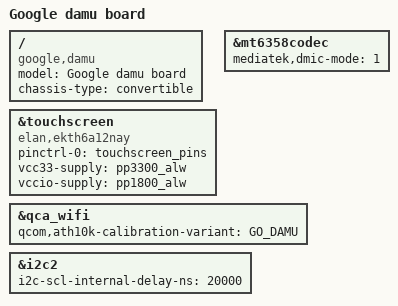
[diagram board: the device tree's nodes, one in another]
// SPDX-License-Identifier: (GPL-2.0 OR MIT)
/*
 * Copyright 2021 Google LLC
 */

/dts-v1/;
#include "mt8183-kukui-jacuzzi.dtsi"
#include "mt8183-kukui-audio-da7219-max98357a.dtsi"

/ {
	model = "Google damu board";
	chassis-type = "convertible";
	compatible = "google,damu", "mediatek,mt8183";
};

&touchscreen {
	compatible = "elan,ekth6a12nay";

	pinctrl-names = "default";
	pinctrl-0 = <&touchscreen_pins>;

	vcc33-supply = <&pp3300_alw>;
	vccio-supply = <&pp1800_alw>;
};

&mt6358codec {
	mediatek,dmic-mode = <1>; /* one-wire */
};

&qca_wifi {
	qcom,ath10k-calibration-variant = "GO_DAMU";
};

&i2c2 {
	i2c-scl-internal-delay-ns = <20000>;
};
